# PRM_GFX register map
Vendor: Texas Instruments
Peripheral module from a debugger description file (folder am437x).
Registers are 32-bit, access per field, no defined reset value unless marked. A register's access mark holds for its fields unless they carry their own. Offsets are as the file gives them; lines under a group give offsets from that group; [hi:lo] are bit positions; {n}, {i} and the like mark numbered series; 'fields as' and 'values as' point back to an identical list; <NAME> marks a mode.

## PRM_GFX
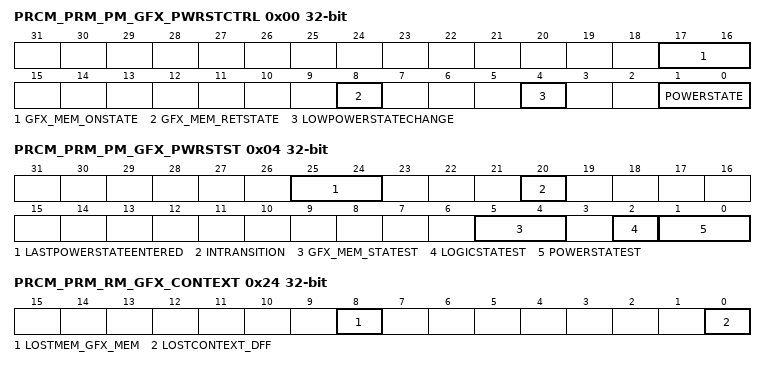
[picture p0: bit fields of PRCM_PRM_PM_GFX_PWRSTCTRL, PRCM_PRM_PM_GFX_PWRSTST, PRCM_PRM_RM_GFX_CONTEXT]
0x00 PRCM_PRM_PM_GFX_PWRSTCTRL — This register controls the GFX power state to reach upon a domain sleep transition.
  [17:16] GFX_MEM_ONSTATE ro — GFX memory state when domain is ON.
    3=en_1_0x3 (Memory bank is on when the domain is ON.)
  [8] GFX_MEM_RETSTATE rw — GFX_MEM bank state when domain is retention
    1=en_2_0x1 (Memory is retained when domain is in RETENTION state.); 0=en_1_0x0 (Memory is off when the domain is in the RETENTION state.)
  [4] LOWPOWERSTATECHANGE rw — Power state change request when domain has already performed a sleep transition. [[br]]Allows going into deeper low power state without waking up the power domain.
    1=en_2_0x1 (Request a low power state change. This bit is automatically cleared when the power state is effectively changed or when power state is ON.); 0=en_1_0x0 (Do not request a low power state change.)
  [1:0] POWERSTATE rw — Power state control
    3=en_4_0x3 (ON State); 2=en_3_0x2 (RESERVED); 1=en_2_0x1 (RESERVED); 0=en_1_0x0 (OFF State)
0x04 PRCM_PRM_PM_GFX_PWRSTST — This register provides a status on the current GFX power domain state. [warm reset insensitive]
  [25:24] LASTPOWERSTATEENTERED rw — Last low power state entered. [[br]]Set to 0x3 upon write of the same only. [[br]]This register is intended for debug purpose only.
    3=en_4_0x3 (Power domain was previously ON-ACTIVE); 2=en_3_0x2 (Power domain was previously ON-INACTIVE); 1=en_2_0x1 (Power domain was previously in RETENTION); 0=en_1_0x0 (Power domain was previously OFF)
  [20] INTRANSITION ro — Domain transition status
    1=en_2_0x1 (Power domain transition is in progress.); 0=en_1_0x0 (No on-going transition on power domain)
  [5:4] GFX_MEM_STATEST ro — GFX memory state status
    3=en_4_0x3 (Memory is ON); 2=en_3_0x2 (Reserved); 1=en_2_0x1 (Memory is in RETENTION.); 0=en_1_0x0 (Memory is OFF)
  [2] LOGICSTATEST ro — Logic state status
    1=en_2_0x1 (Logic in domain is ON); 0=en_1_0x0 (Logic in domain is OFF)
  [1:0] POWERSTATEST ro — Current Power State Status
    3=en_2_0x3 (ON State [warm reset insensitive]); 0=en_1_0x0 (OFF State [warm reset insensitive])
0x10 PRCM_PRM_RM_GFX_RSTCTRL — This register controls the release of the GFX Domain resets.
  [0] GFX_RST rw — GFX domain local reset control
    1=en_2_0x1 (Reset is asserted for the GFX Domain (SGX 530)); 0=en_1_0x0 (Reset is cleared for the GFX Domain (SGX530))
0x14 PRCM_PRM_RM_GFX_RSTST — This register logs the different reset sources of the GFX domain. Each bit is set upon release of the domain reset signal. Must be cleared by software. [warm reset insensitive]
  [0] GFX_RST rw — GFX Domain Logic Reset
    1=en_2_0x1 (GFX Domain Logic has been reset upon SW reset); 0=en_1_0x0 (No SW reset occured)
0x24 PRCM_PRM_RM_GFX_CONTEXT — This register contains dedicated GFX context statuses. [warm reset insensitive]
  [8] LOSTMEM_GFX_MEM rw — Specify if memory-based context in GFX_MEM memory bank has been lost due to a previous power transition or other reset source.
    1=en_2_0x1 (Context has been lost); 0=en_1_0x0 (Context has been maintained)
  [0] LOSTCONTEXT_DFF rw — Specify if DFF-based context has been lost due to a previous power transition or other reset source. [[br]](set upon assertion of GFX_RST signal)
    values as LOSTMEM_GFX_MEM
